VERSION "created by canmatrix"

NS_ :

BS_:

BU_: PCM1 FOO

BO_ 300 Message_C: 8 Vector__XXX
 SG_ Signal_Sine_Shifted : 0|64@1- (1,0) [-1.7E+308|1.7E+308] "V" Vector__XXX

BO_ 400 Message_D: 2 Vector__XXX
 SG_ Signal_Triangle : 8|8@1- (1,0) [-128|127] "" Vector__XXX
 SG_ Signal_Random : 0|8@1+ (1,0) [0|255] "degC" Vector__XXX

BO_ 200 Message_B: 8 Vector__XXX
 SG_ Signal_Sine : 0|64@1- (1,0) [-1.7E+308|1.7E+308] "V" Vector__XXX

BO_ 100 Message_A: 4 Vector__XXX
 SG_ Signal_Step_Counter : 16|16@1+ (1,0) [0|65535] "N" Vector__XXX
 SG_ Signal_PWM : 0|16@1+ (1,0) [0|65535] "N" Vector__XXX

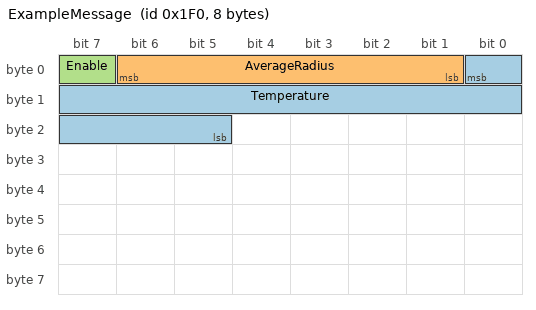
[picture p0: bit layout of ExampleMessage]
BO_ 496 ExampleMessage: 8 PCM1
 SG_ Temperature : 0|12@0- (0.01,250) [229.52|270.47] "degK" PCM1,FOO
 SG_ AverageRadius : 6|6@0+ (0.1,0) [0|5] "m" Vector__XXX
 SG_ Enable : 7|1@0+ (1,0) [0|0] "-" Vector__XXX

CM_ BO_ 496  "Example message used as template in MotoHawk models.";

BA_DEF_ BO_ "CANFD_BRS" ENUM  "0","1";
BA_DEF_ BO_ "VFrameFormat" ENUM  "StandardCAN","ExtendedCAN","reserved","reserved","reserved","reserved","reserved","reserved","reserved","reserved","reserved","reserved","reserved","reserved","StandardCAN_FD","ExtendedCAN_FD";
BA_DEF_  "BusType" STRING;
BA_DEF_  "DBName" STRING;
BA_DEF_DEF_ "BusType" "";
BA_DEF_DEF_ "CANFD_BRS" "1";
BA_DEF_DEF_ "DBName" "";
BA_DEF_DEF_ "VFrameFormat" "StandardCAN";

BA_ "BusType"   "CAN";
BA_ "DBName"   "CANExplorerDatabase";

VAL_ 496 Enable 0 "Disabled" 1 "Enabled";
SIG_VALTYPE_ 300 Signal_Sine_Shifted : 2;
SIG_VALTYPE_ 200 Signal_Sine : 2;
